# nrf9120 register map
Vendor: Nordic Semiconductor; Series: nrf91; File version: 1
CPU: CM33 r0p4, little endian, MPU, FPU, 3 interrupt priority bits, 69 interrupts
Registers are 32-bit, read-write, reset 0x0 unless marked. A register's access mark holds for its fields unless they carry their own. Offsets are from the block's base; [hi:lo] are bit positions; {n}, {i} and the like mark numbered series.

## CC_HOST_RGF_S — CRYPTOCELL HOST register interface
Base 0x50841000; alternate view of CC_AES_S
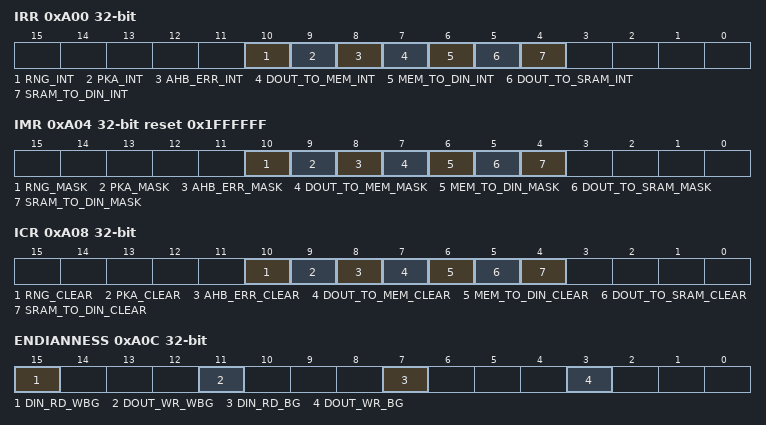
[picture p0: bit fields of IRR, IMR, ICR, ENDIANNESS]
0xA00 IRR ro — Interrupt request register. Each bit of this register holds the interrupt status of a single interrupt source. If corresponding IMR bit is unmasked, an interrupt is generated.
  [10] RNG_INT — The RNG interrupt status.
  [9] PKA_INT — The PKA end of operation interrupt status.
  [8] AHB_ERR_INT — The AHB error interrupt status.
  [7] DOUT_TO_MEM_INT — The DOUT to memory DMA done interrupt status. This interrupt is asserted when all data was delivered from DOUT buffer to memory.
  [6] MEM_TO_DIN_INT — The memory to DIN DMA done interrupt status. This interrupt is asserted when all data was delivered from memory to DIN buffer.
  [5] DOUT_TO_SRAM_INT — The DOUT to RNG SRAM DMA done interrupt status. This interrupt is asserted when all data was delivered from DOUT buffer to RNG SRAM.
  [4] SRAM_TO_DIN_INT — The RNG SRAM to DIN DMA done interrupt status. This interrupt is asserted when all data was delivered from RNG SRAM to DIN buffer.
0xA04 IMR reset 0x1FFFFFF — Interrupt mask register. Each bit of this register holds the mask of a single interrupt source.
  [10] RNG_MASK — The RNG interrupt mask.
    0=IRQEnable (Do not mask RNG interrupt i.e. interrupt is generated); 1=IRQDisable (Mask RNG interrupt i.e. no interrupt is generated)
  [9] PKA_MASK — The PKA end of operation interrupt mask.
    0=IRQEnable (Do not mask PKA end of operation interrupt i.e. interrupt is generated); 1=IRQDisable (Mask PKA end of operation interrupt i.e. no interrupt is generated)
  [8] AHB_ERR_MASK — The AHB error interrupt mask.
    0=IRQEnable (Do not mask AHB error interrupt i.e. interrupt is generated); 1=IRQDisable (Mask AHB error interrupt i.e. no interrupt is generated)
  [7] DOUT_TO_MEM_MASK — The DOUT to memory DMA done interrupt mask.
    0=IRQEnable (Do not mask DOUT to memory DMA done interrupt i.e. interrupt is generated); 1=IRQDisable (Mask DOUT to memory DMA done interrupt i.e. no interrupt is generated)
  [6] MEM_TO_DIN_MASK — The memory to DIN DMA done interrupt mask.
    0=IRQEnable (Do not mask memory to DIN DMA done interrupt i.e. interrupt is generated); 1=IRQDisable (Mask memory to DIN DMA done interrupt i.e. no interrupt is generated)
  [5] DOUT_TO_SRAM_MASK — The DOUT to RNG SRAM DMA done interrupt mask.
    0=IRQEnable (Do not mask DOUT to RNG SRAM DMA done interrupt i.e. interrupt is generated); 1=IRQDisable (Mask DOUT to RNG SRAM DMA done interrupt i.e. no interrupt is generated)
  [4] SRAM_TO_DIN_MASK — The RNG SRAM to DIN DMA done interrupt mask.
    0=IRQEnable (Do not mask RNG SRAM to DIN DMA done interrupt i.e. interrupt is generated); 1=IRQDisable (Mask RNG SRAM to DIN DMA done interrupt i.e. no interrupt is generated)
0xA08 ICR wo — Interrupt clear register. Writing a 1 bit into a field in this register will clear the corresponding bit in IRR.
  [10] RNG_CLEAR — The RNG interrupt clear. Register RNG_ISR in the RNG engine must be cleared before this interrupt can be cleared.
  [9] PKA_CLEAR — The PKA end of operation interrupt clear.
  [8] AHB_ERR_CLEAR — The AHB error interrupt clear.
  [7] DOUT_TO_MEM_CLEAR — The DOUT to memory DMA done interrupt clear.
  [6] MEM_TO_DIN_CLEAR — The memory to DIN DMA done interrupt clear.
  [5] DOUT_TO_SRAM_CLEAR — The DOUT to RNG SRAM DMA done interrupt clear.
  [4] SRAM_TO_DIN_CLEAR — The RNG SRAM to DIN DMA done interrupt clear.
0xA0C ENDIANNESS — This register defines the endianness of the Host-accessible registers, and can only be written once.
  [15] DIN_RD_WBG — DIN read word endianness.
    0=LittleEndian (Configure DIN read word as little-endian); 1=BigEndian (Configure DIN read word as big-endian)
  [11] DOUT_WR_WBG — DOUT write word endianness.
    0=LittleEndian (Configure DOUT write word as little-endian); 1=BigEndian (Configure DOUT write word as big-endian)
  [7] DIN_RD_BG — DIN read endianness.
    0=LittleEndian (Configure DIN read as little-endian); 1=BigEndian (Configure DIN read as big-endian)
  [3] DOUT_WR_BG — DOUT write endianness.
    0=LittleEndian (Configure DOUT write as little-endian); 1=BigEndian (Configure DOUT write as big-endian)
0xA24 HOST_SIGNATURE ro reset 0x20E00000 — This register holds the CRYPTOCELL subsystem signature. See reset value.
  [31:0] VALUE — Fixed-value identification signature used by host driver to verify CRYPTOCELL presence at this address.
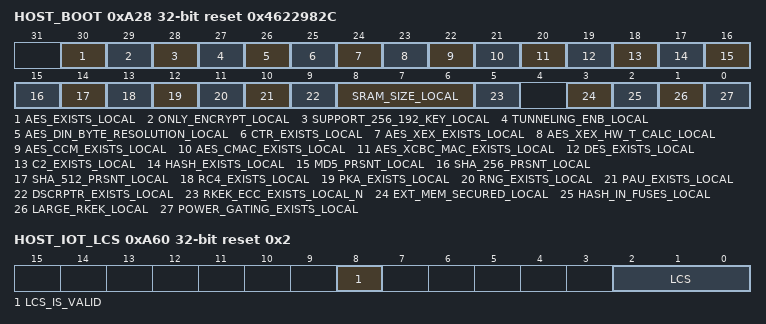
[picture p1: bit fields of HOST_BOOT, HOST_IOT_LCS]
0xA28 HOST_BOOT ro reset 0x4622982C — Hardware configuration of the CRYPTOCELL subsystem. Reset value holds the supported features.
  [30] AES_EXISTS_LOCAL — If this flag is set, the AES engine is present
  [29] ONLY_ENCRYPT_LOCAL — If this flag is set, the AES engine only support encryption
  [28] SUPPORT_256_192_KEY_LOCAL — If this flag is set, the AES engine supports 192/256 bits key sizes
  [27] TUNNELING_ENB_LOCAL — If this flag is set, the AES engine supports tunneling operations
  [26] AES_DIN_BYTE_RESOLUTION_LOCAL — If this flag is set, the AES engine data input support byte size resolution
  [25] CTR_EXISTS_LOCAL — If this flag is set, AES CTR mode is supported
  [24] AES_XEX_EXISTS_LOCAL — If this flag is set, AES XEX mode is supported
  [23] AES_XEX_HW_T_CALC_LOCAL — If this flag is set, AES XEX mode T-value calculation in HW is supported
  [22] AES_CCM_EXISTS_LOCAL — If this flag is set, AES CCM mode is supported
  [21] AES_CMAC_EXISTS_LOCAL — If this flag is set, AES CMAC mode is supported
  [20] AES_XCBC_MAC_EXISTS_LOCAL — If this flag is set, AES XCBC-MAC mode is supported
  [19] DES_EXISTS_LOCAL — If this flag is set, the DES engine is present
  [18] C2_EXISTS_LOCAL — If this flag is set, the C2 engine is present
  [17] HASH_EXISTS_LOCAL — If this flag is set, the HASH engine is present
  [16] MD5_PRSNT_LOCAL — If this flag is set, the HASH engine supports MD5
  [15] SHA_256_PRSNT_LOCAL — If this flag is set, the HASH engine supports SHA256
  [14] SHA_512_PRSNT_LOCAL — If this flag is set, the HASH engine supports SHA512
  [13] RC4_EXISTS_LOCAL — If this flag is set, the RC4 engine is present
  [12] PKA_EXISTS_LOCAL — If this flag is set, the PKA engine is present
  [11] RNG_EXISTS_LOCAL — If this flag is set, the RNG engine is present
  [10] PAU_EXISTS_LOCAL — If this flag is set, PAU is supported
  [9] DSCRPTR_EXISTS_LOCAL — If this flag is set, Descriptors are supported
  [8:6] SRAM_SIZE_LOCAL — SRAM size
  [5] RKEK_ECC_EXISTS_LOCAL_N — If this flag is set, RKEK ECC is supported
  [3] EXT_MEM_SECURED_LOCAL — If this flag is set, external secure memory is supported
  [2] HASH_IN_FUSES_LOCAL — If this flag is set, HASH in fuses is supported
  [1] LARGE_RKEK_LOCAL — If this flag is set, large RKEK is supported
  [0] POWER_GATING_EXISTS_LOCAL — If this flag is set, full power gating is implemented
0xA38 HOST_CRYPTOKEY_SEL — AES hardware key select.
  [1:0] HOST_CRYPTOKEY_SEL — Select the source of the HW key that is used by the AES engine
    0=K_DR (Use device root key K_DR from CRYPTOCELL AO power domain); 1=K_PRTL (Use hard-coded RTL key K_PRTL); 2=Session (Use provided session key)
0xA4C HOST_IOT_KPRTL_LOCK rw-once — This write-once register is the K_PRTL lock register. When this register is set, K_PRTL cannot be used and a zeroed key will be used instead. The value of this register is saved in the CRYPTOCELL AO power domain.
  [0] HOST_IOT_KPRTL_LOCK — This register is the K_PRTL lock register. When this register is set, K_PRTL cannot be used and a zeroed key will be used instead. The value of this register is saved in the CRYPTOCELL AO power domain.
    0=Disabled (K_PRTL can be selected for use from register HOST_CRYPTOKEY_SEL); 1=Enabled (K_PRTL has been locked until next power-on reset (POR). If K_PRTL is selected anyway, a zeroed key will be used instead.)
0xA50 HOST_IOT_KDR0 rw-once — This register holds bits 31:0 of K_DR. The value of this register is saved in the CRYPTOCELL AO power domain. Reading from this address returns the K_DR valid status indicating if K_DR is successfully retained.
  [31:0] HOST_IOT_KDR0 — This register holds bits 31:0 of K_DR. The value of this register is saved in the CRYPTOCELL AO power domain. Reading from this address returns the K_DR valid status indicating if K_DR is successfully retained. Write: K_DR bits 31:0.
    0=NotRetained (Read: 128 bits K_DR key value is not yet retained in the CRYPTOCELL AO power domain.); 1=Retained (Read: 128 bits K_DR key value is successfully retained in the CRYPTOCELL AO power domain.)
{0xA50+4i} HOST_IOT_KDR{i} write-once (i=1..3) — This register holds bits {32i+31}:{32i} of K_DR. The value of this register is saved in the CRYPTOCELL AO power domain.
  [31:0] HOST_IOT_KDR{i} — K_DR bits {32i+31}:{32i}
0xA60 HOST_IOT_LCS reset 0x2 — Controls life-cycle state (LCS) for CRYPTOCELL subsystem
  [8] LCS_IS_VALID ro — Read-only field. Indicates if CRYPTOCELL LCS has been successfully configured since last reset.
    0=Invalid (Valid LCS not yet retained in the CRYPTOCELL AO power domain); 1=Valid LCS successfully retained in the CRYPTOCELL AO power domain
  [2:0] LCS rw-once — Life-cycle state value. This field is write-once per reset.
    0=DebugEnable (CC310 operates in debug mode); 2=Secure (CC310 operates in secure mode)
